# ADUC7023 register map
File version: 1.0
Registers are 32-bit, read-write, reset 0x0 unless marked. A register's access mark holds for its fields unless they carry their own. Offsets are from the block's base; [hi:lo] are bit positions; {n}, {i} and the like mark numbered series.

## I2C0 — I2C0 peripheral interfaces
Base 0xFFFF0800
Same registers: I2C1 0xFFFF0900
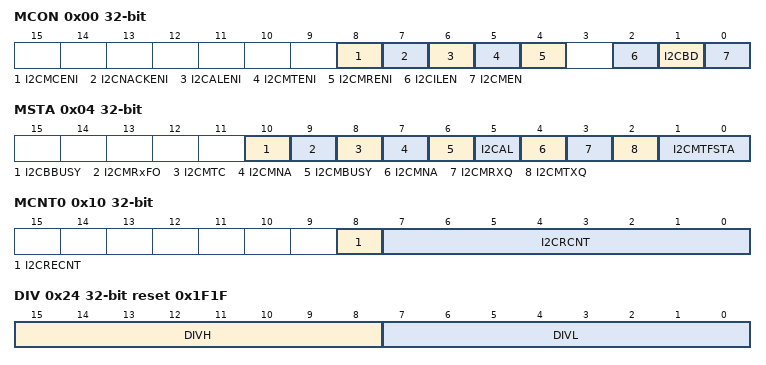
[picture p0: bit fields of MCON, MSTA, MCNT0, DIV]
0x00 MCON — Master control register
  [8] I2CMCENI — Transmission complete interrupt enable bit
  [7] I2CNACKENI — No acknowledge received interrupt enable bit
  [6] I2CALENI — Arbitration lost interrupt enable bit
  [5] I2CMTENI — Transmit interrupt enable bit
  [4] I2CMRENI — Receive interrupt enable bit
  [2] I2CILEN — Internal loopback enable bit
  [1] I2CBD — Master backoff disable bit
  [0] I2CMEN — Master enable bit
0x04 MSTA ro — Master status register
  [10] I2CBBUSY — Bus busy status bit
  [9] I2CMRxFO — Master Rx FIFO overflow
  [8] I2CMTC — Transmission complete status bit
  [7] I2CMNA — Master no acknowledge data bit
  [6] I2CMBUSY — Master busy status bit
  [5] I2CAL — Arbitration lost status bit
  [4] I2CMNA — Master no acknowledge address bit
  [3] I2CMRXQ — Master receive request bit
  [2] I2CMTXQ — Master transmit request bit
  [1:0] I2CMTFSTA — Master Tx FIFO status bit
0x08 MRX ro — Master receive register
  [7:0] MRX
0x0C MTX wo — Master transmit register
  [7:0] MTX
0x10 MCNT0 — Master read count register
  [8] I2CRECNT — Master read count register
  [7:0] I2CRCNT — Master read count register
0x14 MCNT1 ro — Master current read count register
  [7:0] I2CCRCNT
0x18 ADR0 — Address byte register
  [7:0] I2CADR
0x1C ADR1 — Address byte register
  [7:0] I2CLADR
0x24 DIV reset 0x1F1F — Clock control register
  [15:8] DIVH — Clock control register
  [7:0] DIVL — Clock control register
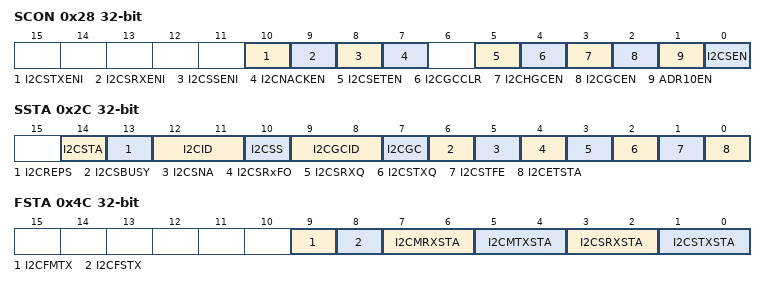
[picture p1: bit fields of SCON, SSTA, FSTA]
0x28 SCON — Slave control register
  [10] I2CSTXENI — Slave transmit interrupt enable bit
  [9] I2CSRXENI — Slave receive interrupt enable bit
  [8] I2CSSENI — Stop condition detected interrupt enable bit
  [7] I2CNACKEN — No acknowledge enable bit
  [5] I2CSETEN — Early transmit interrupt enable bit
  [4] I2CGCCLR — General call status and ID clear bit
  [3] I2CHGCEN — Hardware general call enable
  [2] I2CGCEN — General call enable
  [1] ADR10EN — 10-bit address mode
  [0] I2CSEN — Slave enable bit
0x2C SSTA — Slave status register
  [14] I2CSTA — Start condition followed by a matching address is detected
  [13] I2CREPS — Repeated start condition is detected
  [12:11] I2CID — Address matching register
  [10] I2CSS — Stop condition after start detected bit
  [9:8] I2CGCID — General call ID bits
  [7] I2CGC — General call status bit
  [6] I2CSBUSY — Slave busy status bit
  [5] I2CSNA — Slave no acknowledge data bit
  [4] I2CSRxFO — Slave Rx FIFO overflow
  [3] I2CSRXQ — Slave receive request bit
  [2] I2CSTXQ — Slave transmit request bit
  [1] I2CSTFE — Slave FIFO underflow status bit
  [0] I2CETSTA — Slave early transmit FIFO status bit
0x30 SRX ro — Slave receive register
  [7:0] SRX
0x34 STX wo — Slave transmit register
  [7:0] STX
0x38 ALT — Hardware general call recognition register
  [7:0] I2CALT
{0x3C+4i} ID{i} (i=0..3) — Slave ID{i} register
  [7:0] I2CID{i}
0x4C FSTA — FIFO status register
  [9] I2CFMTX — Flush the master Tx FIFO
  [8] I2CFSTX — Flush the slave Tx FIFO
  [7:6] I2CMRXSTA — Master receive FIFO status bits
  [5:4] I2CMTXSTA — Master transmit FIFO status bits
  [3:2] I2CSRXSTA — Slave receive FIFO status bits
  [1:0] I2CSTXSTA — Slave transmit FIFO status bits

## FLASH — FLASH/EE CONTROL INTERFACE
Base 0xFFFFF800
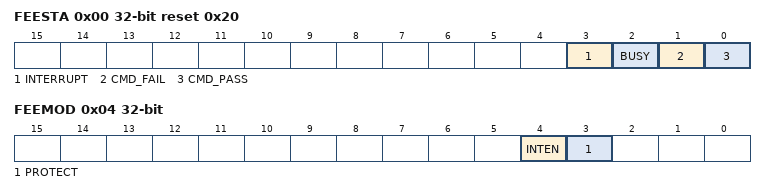
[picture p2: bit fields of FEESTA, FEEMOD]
0x00 FEESTA ro reset 0x20 — Flash/EE status MMR
  [3] INTERRUPT — Set automatically when an interrupt occurs
  [2] BUSY — Controller busy
  [1] CMD_FAIL — Command is not completed
  [0] CMD_PASS — Command is completed
0x04 FEEMOD — Flash/EE control MMR
  [4] INTEN — Flash/EE interrupt enable
  [3] PROTECT — Erase/write command protection
0x08 FEECON reset 0x7 — 8-bit command register
  [7:0] CMD — Command code
0x0C FEEDAT — 16-bit data register
  [15:0] DAT
0x10 FEEADR — 16-bit address register
  [15:0] ADR
0x18 FEESIGN ro reset 0xFFFFFF — 24-bit code signature
  [23:0] SIGN
0x1C FEEPRO — Provide protection
  [31:0] PRO
0x20 FEEHIDE reset 0xFFFFFFFF — Provide immediate protection
  [31:0] HIDE
